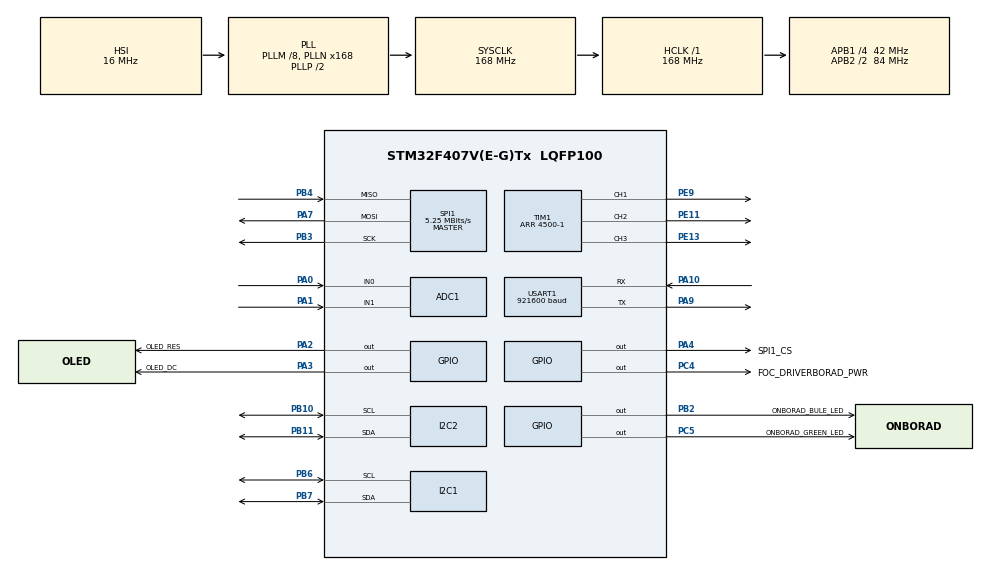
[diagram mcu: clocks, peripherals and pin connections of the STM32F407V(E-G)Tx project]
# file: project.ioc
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ADC1.Channel-4\#ChannelRegularConversion=ADC_CHANNEL_0
ADC1.Channel-8\#ChannelInjectedConversion=ADC_CHANNEL_0
ADC1.Channel-9\#ChannelInjectedConversion=ADC_CHANNEL_1
ADC1.ExternalTrigInjecConv=ADC_EXTERNALTRIGINJECCONV_T1_TRGO
ADC1.InjNumberOfConversion=2
ADC1.InjectedConvMode=None
ADC1.InjectedOffset-8\#ChannelInjectedConversion=0
ADC1.InjectedOffset-9\#ChannelInjectedConversion=0
ADC1.InjectedRank-8\#ChannelInjectedConversion=1
ADC1.InjectedRank-9\#ChannelInjectedConversion=2
ADC1.NbrOfConversion=1
ADC1.NbrOfConversionFlag=1
ADC1.Rank-4\#ChannelRegularConversion=1
ADC1.SamplingTime-4\#ChannelRegularConversion=ADC_SAMPLETIME_3CYCLES
ADC1.SamplingTime-8\#ChannelInjectedConversion=ADC_SAMPLETIME_15CYCLES
ADC1.SamplingTime-9\#ChannelInjectedConversion=ADC_SAMPLETIME_15CYCLES
ADC1.ScanConvMode=ENABLE
ADC1.master=1
Dma.I2C1_RX.1.Direction=DMA_PERIPH_TO_MEMORY
Dma.I2C1_RX.1.FIFOMode=DMA_FIFOMODE_DISABLE
Dma.I2C1_RX.1.Instance=DMA1_Stream0
Dma.I2C1_RX.1.MemDataAlignment=DMA_MDATAALIGN_BYTE
Dma.I2C1_RX.1.MemInc=DMA_MINC_ENABLE
Dma.I2C1_RX.1.Mode=DMA_NORMAL
Dma.I2C1_RX.1.PeriphDataAlignment=DMA_PDATAALIGN_BYTE
Dma.I2C1_RX.1.PeriphInc=DMA_PINC_DISABLE
Dma.I2C1_RX.1.Priority=DMA_PRIORITY_LOW
Dma.I2C2_RX.2.Direction=DMA_PERIPH_TO_MEMORY
Dma.I2C2_RX.2.FIFOMode=DMA_FIFOMODE_DISABLE
Dma.I2C2_RX.2.Instance=DMA1_Stream2
Dma.I2C2_RX.2.MemDataAlignment=DMA_MDATAALIGN_BYTE
Dma.I2C2_RX.2.MemInc=DMA_MINC_ENABLE
Dma.I2C2_RX.2.Mode=DMA_NORMAL
Dma.I2C2_RX.2.PeriphDataAlignment=DMA_PDATAALIGN_BYTE
Dma.I2C2_RX.2.PeriphInc=DMA_PINC_DISABLE
Dma.I2C2_RX.2.Priority=DMA_PRIORITY_LOW
Dma.Request0=USART1_TX
Dma.Request1=I2C1_RX
Dma.Request2=I2C2_RX
Dma.USART1_TX.0.Direction=DMA_MEMORY_TO_PERIPH
Dma.USART1_TX.0.FIFOMode=DMA_FIFOMODE_DISABLE
Dma.USART1_TX.0.Instance=DMA2_Stream7
Dma.USART1_TX.0.MemDataAlignment=DMA_MDATAALIGN_BYTE
Dma.USART1_TX.0.MemInc=DMA_MINC_ENABLE
Dma.USART1_TX.0.Mode=DMA_NORMAL
Dma.USART1_TX.0.PeriphDataAlignment=DMA_PDATAALIGN_BYTE
Dma.USART1_TX.0.PeriphInc=DMA_PINC_DISABLE
Dma.USART1_TX.0.Priority=DMA_PRIORITY_LOW
I2C1.I2C_Mode=I2C_Standard
I2C2.I2C_Mode=I2C_Standard
Mcu.Family=STM32F4
Mcu.Name=STM32F407V(E-G)Tx
Mcu.Package=LQFP100
NVIC.DMA1_Stream0_IRQn=true\:0\:0\:false\:false\:true\:false\:true\:true
NVIC.DMA1_Stream2_IRQn=true\:0\:0\:false\:false\:true\:false\:true\:true
NVIC.DMA2_Stream7_IRQn=true\:0\:0\:false\:false\:true\:false\:true\:true
NVIC.PriorityGroup=NVIC_PRIORITYGROUP_4
NVIC.TIM1_UP_TIM10_IRQn=true\:0\:0\:false\:false\:true\:true\:true\:true
NVIC.USART1_IRQn=true\:0\:0\:false\:false\:true\:true\:true\:true
PA0-WKUP.Signal=ADCx_IN0
PA1.Signal=ADCx_IN1
PA10.Mode=Asynchronous
PA10.Signal=USART1_RX
PA13.Mode=Serial_Wire
PA13.Signal=SYS_JTMS-SWDIO
PA14.Mode=Serial_Wire
PA14.Signal=SYS_JTCK-SWCLK
PA2.GPIO_Label=OLED_RES
PA2.GPIO_PuPd=GPIO_PULLUP
PA2.GPIO_Speed=GPIO_SPEED_FREQ_VERY_HIGH
PA2.PinState=GPIO_PIN_SET
PA2.Signal=GPIO_Output
PA3.GPIO_Label=OLED_DC
PA3.GPIO_PuPd=GPIO_PULLUP
PA3.GPIO_Speed=GPIO_SPEED_FREQ_VERY_HIGH
PA3.PinState=GPIO_PIN_SET
PA3.Signal=GPIO_Output
PA4.GPIO_Label=SPI1_CS
PA4.GPIO_PuPd=GPIO_PULLUP
PA4.GPIO_Speed=GPIO_SPEED_FREQ_VERY_HIGH
PA4.PinState=GPIO_PIN_SET
PA4.Signal=GPIO_Output
PA7.Mode=Full_Duplex_Master
PA7.Signal=SPI1_MOSI
PA9.Mode=Asynchronous
PA9.Signal=USART1_TX
PB10.Mode=I2C
PB10.Signal=I2C2_SCL
PB11.Mode=I2C
PB11.Signal=I2C2_SDA
PB2.GPIO_Label=ONBORAD_BULE_LED
PB2.GPIO_PuPd=GPIO_PULLUP
PB2.PinState=GPIO_PIN_SET
PB2.Signal=GPIO_Output
PB3.Mode=Full_Duplex_Master
PB3.Signal=SPI1_SCK
PB4.Mode=Full_Duplex_Master
PB4.Signal=SPI1_MISO
PB6.Mode=I2C
PB6.Signal=I2C1_SCL
PB7.Mode=I2C
PB7.Signal=I2C1_SDA
PC4.GPIO_Label=FOC_DRIVERBORAD_PWR
PC4.GPIO_PuPd=GPIO_NOPULL
PC4.Signal=GPIO_Output
PC5.GPIO_Label=ONBORAD_GREEN_LED
PC5.GPIO_PuPd=GPIO_PULLUP
PC5.PinState=GPIO_PIN_SET
PC5.Signal=GPIO_Output
PE11.Signal=S_TIM1_CH2
PE13.Signal=S_TIM1_CH3
PE9.Signal=S_TIM1_CH1
PH0-OSC_IN.Mode=HSE-External-Oscillator
PH0-OSC_IN.Signal=RCC_OSC_IN
PH1-OSC_OUT.Mode=HSE-External-Oscillator
PH1-OSC_OUT.Signal=RCC_OSC_OUT
ProjectManager.HeapSize=0x200
ProjectManager.StackSize=0x400
ProjectManager.TargetToolchain=MDK-ARM V5.32
RCC.48MHZClocksFreq_Value=84000000
RCC.AHBFreq_Value=168000000
RCC.APB1CLKDivider=RCC_HCLK_DIV4
RCC.APB1Freq_Value=42000000
RCC.APB1TimFreq_Value=84000000
RCC.APB2CLKDivider=RCC_HCLK_DIV2
RCC.APB2Freq_Value=84000000
RCC.APB2TimFreq_Value=168000000
RCC.CortexFreq_Value=168000000
RCC.HCLKFreq_Value=168000000
RCC.HSE_VALUE=25000000
RCC.HSI_VALUE=16000000
RCC.LSE_VALUE=32768
RCC.PLLM=8
RCC.PLLN=168
RCC.SYSCLKFreq_VALUE=168000000
RCC.SYSCLKSource=RCC_SYSCLKSOURCE_PLLCLK
RCC.VCOOutputFreq_Value=336000000
SH.ADCx_IN0.0=ADC1_IN0,IN0
SH.ADCx_IN1.0=ADC1_IN1,IN1
SH.S_TIM1_CH1.0=TIM1_CH1,PWM Generation1 CH1
SH.S_TIM1_CH2.0=TIM1_CH2,PWM Generation2 CH2
SH.S_TIM1_CH3.0=TIM1_CH3,PWM Generation3 CH3
SPI1.BaudRatePrescaler=SPI_BAUDRATEPRESCALER_16
SPI1.CalculateBaudRate=5.25 MBits/s
SPI1.Direction=SPI_DIRECTION_2LINES
SPI1.Mode=SPI_MODE_MASTER
SPI1.VirtualType=VM_MASTER
TIM1.AutoReloadPreload=TIM_AUTORELOAD_PRELOAD_ENABLE
TIM1.Channel-PWM\ Generation1\ CH1=TIM_CHANNEL_1
TIM1.Channel-PWM\ Generation2\ CH2=TIM_CHANNEL_2
TIM1.Channel-PWM\ Generation3\ CH3=TIM_CHANNEL_3
TIM1.CounterMode=TIM_COUNTERMODE_CENTERALIGNED3
TIM1.Period=4500-1
TIM1.Pulse-PWM\ Generation1\ CH1=2100
TIM1.Pulse-PWM\ Generation2\ CH2=2100
TIM1.Pulse-PWM\ Generation3\ CH3=2100
TIM1.RepetitionCounter=1
TIM1.TIM_MasterOutputTrigger=TIM_TRGO_UPDATE
TIM1.TIM_MasterSlaveMode=TIM_MASTERSLAVEMODE_ENABLE
USART1.BaudRate=921600
USART1.VirtualMode=VM_ASYNC
VP_TIM1_VS_ClockSourceINT.Mode=Internal
board=custom

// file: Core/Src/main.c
/* USER CODE BEGIN Header */
/**
  ******************************************************************************
  * @file           : main.c
  * @brief          : Main program body
  ******************************************************************************
  * @attention
  *
  * Copyright (c) 2026 STMicroelectronics.
  * All rights reserved.
  *
  * This software is licensed under terms that can be found in the LICENSE file
  * in the root directory of this software component.
  * If no LICENSE file comes with this software, it is provided AS-IS.
  *
  ******************************************************************************
  */
/* USER CODE END Header */
#include "main.h"

ADC_HandleTypeDef hadc1;

I2C_HandleTypeDef hi2c1;
I2C_HandleTypeDef hi2c2;
DMA_HandleTypeDef hdma_i2c1_rx;
DMA_HandleTypeDef hdma_i2c2_rx;

SPI_HandleTypeDef hspi1;

TIM_HandleTypeDef htim1;

UART_HandleTypeDef huart1;
DMA_HandleTypeDef hdma_usart1_tx;

void SystemClock_Config(void);
static void MX_GPIO_Init(void);
static void MX_DMA_Init(void);
static void MX_USART1_UART_Init(void);
static void MX_SPI1_Init(void);
static void MX_I2C1_Init(void);
static void MX_TIM1_Init(void);
static void MX_I2C2_Init(void);
static void MX_ADC1_Init(void);

int main(void)
{

  /* MCU Configuration--------------------------------------------------------*/

  /* Reset of all peripherals, Initializes the Flash interface and the Systick. */
  HAL_Init();

  /* Configure the system clock */
  SystemClock_Config();

  /* Initialize all configured peripherals */
  MX_GPIO_Init();
  MX_DMA_Init();
  MX_USART1_UART_Init();
  MX_SPI1_Init();
  MX_I2C1_Init();
  MX_TIM1_Init();
  MX_I2C2_Init();
  MX_ADC1_Init();
  /* USER CODE BEGIN 2 */
  start_init_all();
  /* USER CODE END 2 */

  /* Infinite loop */
  /* USER CODE BEGIN WHILE */
  while (1)
  {
    start_loop();
    /* USER CODE END WHILE */

  }
}

void SystemClock_Config(void)
{
  RCC_OscInitTypeDef RCC_OscInitStruct = {0};
  RCC_ClkInitTypeDef RCC_ClkInitStruct = {0};

  /** Configure the main internal regulator output voltage
  */
  __HAL_RCC_PWR_CLK_ENABLE();
  __HAL_PWR_VOLTAGESCALING_CONFIG(PWR_REGULATOR_VOLTAGE_SCALE1);

  /** Initializes the RCC Oscillators according to the specified parameters
  * in the RCC_OscInitTypeDef structure.
  */
  RCC_OscInitStruct.OscillatorType = RCC_OSCILLATORTYPE_HSI;
  RCC_OscInitStruct.HSIState = RCC_HSI_ON;
  RCC_OscInitStruct.HSICalibrationValue = RCC_HSICALIBRATION_DEFAULT;
  RCC_OscInitStruct.PLL.PLLState = RCC_PLL_ON;
  RCC_OscInitStruct.PLL.PLLSource = RCC_PLLSOURCE_HSI;
  RCC_OscInitStruct.PLL.PLLM = 8;
  RCC_OscInitStruct.PLL.PLLN = 168;
  RCC_OscInitStruct.PLL.PLLP = RCC_PLLP_DIV2;
  RCC_OscInitStruct.PLL.PLLQ = 4;
  if (HAL_RCC_OscConfig(&RCC_OscInitStruct) != HAL_OK)
  {
    Error_Handler();
  }

  /** Initializes the CPU, AHB and APB buses clocks
  */
  RCC_ClkInitStruct.ClockType = RCC_CLOCKTYPE_HCLK|RCC_CLOCKTYPE_SYSCLK
                              |RCC_CLOCKTYPE_PCLK1|RCC_CLOCKTYPE_PCLK2;
  RCC_ClkInitStruct.SYSCLKSource = RCC_SYSCLKSOURCE_PLLCLK;
  RCC_ClkInitStruct.AHBCLKDivider = RCC_SYSCLK_DIV1;
  RCC_ClkInitStruct.APB1CLKDivider = RCC_HCLK_DIV4;
  RCC_ClkInitStruct.APB2CLKDivider = RCC_HCLK_DIV2;

  if (HAL_RCC_ClockConfig(&RCC_ClkInitStruct, FLASH_LATENCY_5) != HAL_OK)
  {
    Error_Handler();
  }
}

static void MX_ADC1_Init(void)
{

  ADC_ChannelConfTypeDef sConfig = {0};
  ADC_InjectionConfTypeDef sConfigInjected = {0};

  /** Configure the global features of the ADC (Clock, Resolution, Data Alignment and number of conversion)
  */
  hadc1.Instance = ADC1;
  hadc1.Init.ClockPrescaler = ADC_CLOCK_SYNC_PCLK_DIV4;
  hadc1.Init.Resolution = ADC_RESOLUTION_12B;
  hadc1.Init.ScanConvMode = ENABLE;
  hadc1.Init.ContinuousConvMode = DISABLE;
  hadc1.Init.DiscontinuousConvMode = DISABLE;
  hadc1.Init.ExternalTrigConvEdge = ADC_EXTERNALTRIGCONVEDGE_NONE;
  hadc1.Init.ExternalTrigConv = ADC_SOFTWARE_START;
  hadc1.Init.DataAlign = ADC_DATAALIGN_RIGHT;
  hadc1.Init.NbrOfConversion = 1;
  hadc1.Init.DMAContinuousRequests = DISABLE;
  hadc1.Init.EOCSelection = ADC_EOC_SINGLE_CONV;
  if (HAL_ADC_Init(&hadc1) != HAL_OK)
  {
    Error_Handler();
  }

  /** Configure for the selected ADC regular channel its corresponding rank in the sequencer and its sample time.
  */
  sConfig.Channel = ADC_CHANNEL_0;
  sConfig.Rank = 1;
  sConfig.SamplingTime = ADC_SAMPLETIME_3CYCLES;
  if (HAL_ADC_ConfigChannel(&hadc1, &sConfig) != HAL_OK)
  {
    Error_Handler();
  }

  /** Configures for the selected ADC injected channel its corresponding rank in the sequencer and its sample time
  */
  sConfigInjected.InjectedChannel = ADC_CHANNEL_0;
  sConfigInjected.InjectedRank = 1;
  sConfigInjected.InjectedNbrOfConversion = 2;
  sConfigInjected.InjectedSamplingTime = ADC_SAMPLETIME_15CYCLES;
  sConfigInjected.ExternalTrigInjecConvEdge = ADC_EXTERNALTRIGINJECCONVEDGE_RISING;
  sConfigInjected.ExternalTrigInjecConv = ADC_EXTERNALTRIGINJECCONV_T1_TRGO;
  sConfigInjected.AutoInjectedConv = DISABLE;
  sConfigInjected.InjectedDiscontinuousConvMode = DISABLE;
  sConfigInjected.InjectedOffset = 0;
  if (HAL_ADCEx_InjectedConfigChannel(&hadc1, &sConfigInjected) != HAL_OK)
  {
    Error_Handler();
  }

  /** Configures for the selected ADC injected channel its corresponding rank in the sequencer and its sample time
  */
  sConfigInjected.InjectedChannel = ADC_CHANNEL_1;
  sConfigInjected.InjectedRank = 2;
  if (HAL_ADCEx_InjectedConfigChannel(&hadc1, &sConfigInjected) != HAL_OK)
  {
    Error_Handler();
  }

}

static void MX_I2C1_Init(void)
{

  hi2c1.Instance = I2C1;
  hi2c1.Init.ClockSpeed = 100000;
  hi2c1.Init.DutyCycle = I2C_DUTYCYCLE_2;
  hi2c1.Init.OwnAddress1 = 0;
  hi2c1.Init.AddressingMode = I2C_ADDRESSINGMODE_7BIT;
  hi2c1.Init.DualAddressMode = I2C_DUALADDRESS_DISABLE;
  hi2c1.Init.OwnAddress2 = 0;
  hi2c1.Init.GeneralCallMode = I2C_GENERALCALL_DISABLE;
  hi2c1.Init.NoStretchMode = I2C_NOSTRETCH_DISABLE;
  if (HAL_I2C_Init(&hi2c1) != HAL_OK)
  {
    Error_Handler();
  }

}

static void MX_I2C2_Init(void)
{

  hi2c2.Instance = I2C2;
  hi2c2.Init.ClockSpeed = 100000;
  hi2c2.Init.DutyCycle = I2C_DUTYCYCLE_2;
  hi2c2.Init.OwnAddress1 = 0;
  hi2c2.Init.AddressingMode = I2C_ADDRESSINGMODE_7BIT;
  hi2c2.Init.DualAddressMode = I2C_DUALADDRESS_DISABLE;
  hi2c2.Init.OwnAddress2 = 0;
  hi2c2.Init.GeneralCallMode = I2C_GENERALCALL_DISABLE;
  hi2c2.Init.NoStretchMode = I2C_NOSTRETCH_DISABLE;
  if (HAL_I2C_Init(&hi2c2) != HAL_OK)
  {
    Error_Handler();
  }

}

static void MX_SPI1_Init(void)
{

  /* SPI1 parameter configuration*/
  hspi1.Instance = SPI1;
  hspi1.Init.Mode = SPI_MODE_MASTER;
  hspi1.Init.Direction = SPI_DIRECTION_2LINES;
  hspi1.Init.DataSize = SPI_DATASIZE_8BIT;
  hspi1.Init.CLKPolarity = SPI_POLARITY_LOW;
  hspi1.Init.CLKPhase = SPI_PHASE_1EDGE;
  hspi1.Init.NSS = SPI_NSS_SOFT;
  hspi1.Init.BaudRatePrescaler = SPI_BAUDRATEPRESCALER_16;
  hspi1.Init.FirstBit = SPI_FIRSTBIT_MSB;
  hspi1.Init.TIMode = SPI_TIMODE_DISABLE;
  hspi1.Init.CRCCalculation = SPI_CRCCALCULATION_DISABLE;
  hspi1.Init.CRCPolynomial = 10;
  if (HAL_SPI_Init(&hspi1) != HAL_OK)
  {
    Error_Handler();
  }

}

static void MX_TIM1_Init(void)
{

  TIM_ClockConfigTypeDef sClockSourceConfig = {0};
  TIM_MasterConfigTypeDef sMasterConfig = {0};
  TIM_OC_InitTypeDef sConfigOC = {0};
  TIM_BreakDeadTimeConfigTypeDef sBreakDeadTimeConfig = {0};

  htim1.Instance = TIM1;
  htim1.Init.Prescaler = 0;
  htim1.Init.CounterMode = TIM_COUNTERMODE_CENTERALIGNED3;
  htim1.Init.Period = 4500-1;
  htim1.Init.ClockDivision = TIM_CLOCKDIVISION_DIV1;
  htim1.Init.RepetitionCounter = 1;
  htim1.Init.AutoReloadPreload = TIM_AUTORELOAD_PRELOAD_ENABLE;
  if (HAL_TIM_Base_Init(&htim1) != HAL_OK)
  {
    Error_Handler();
  }
  sClockSourceConfig.ClockSource = TIM_CLOCKSOURCE_INTERNAL;
  if (HAL_TIM_ConfigClockSource(&htim1, &sClockSourceConfig) != HAL_OK)
  {
    Error_Handler();
  }
  if (HAL_TIM_PWM_Init(&htim1) != HAL_OK)
  {
    Error_Handler();
  }
  sMasterConfig.MasterOutputTrigger = TIM_TRGO_UPDATE;
  sMasterConfig.MasterSlaveMode = TIM_MASTERSLAVEMODE_ENABLE;
  if (HAL_TIMEx_MasterConfigSynchronization(&htim1, &sMasterConfig) != HAL_OK)
  {
    Error_Handler();
  }
  sConfigOC.OCMode = TIM_OCMODE_PWM1;
  sConfigOC.Pulse = 2100;
  sConfigOC.OCPolarity = TIM_OCPOLARITY_HIGH;
  sConfigOC.OCNPolarity = TIM_OCNPOLARITY_HIGH;
  sConfigOC.OCFastMode = TIM_OCFAST_DISABLE;
  sConfigOC.OCIdleState = TIM_OCIDLESTATE_RESET;
  sConfigOC.OCNIdleState = TIM_OCNIDLESTATE_RESET;
  if (HAL_TIM_PWM_ConfigChannel(&htim1, &sConfigOC, TIM_CHANNEL_1) != HAL_OK)
  {
    Error_Handler();
  }
  if (HAL_TIM_PWM_ConfigChannel(&htim1, &sConfigOC, TIM_CHANNEL_2) != HAL_OK)
  {
    Error_Handler();
  }
  if (HAL_TIM_PWM_ConfigChannel(&htim1, &sConfigOC, TIM_CHANNEL_3) != HAL_OK)
  {
    Error_Handler();
  }
  sBreakDeadTimeConfig.OffStateRunMode = TIM_OSSR_DISABLE;
  sBreakDeadTimeConfig.OffStateIDLEMode = TIM_OSSI_DISABLE;
  sBreakDeadTimeConfig.LockLevel = TIM_LOCKLEVEL_OFF;
  sBreakDeadTimeConfig.DeadTime = 0;
  sBreakDeadTimeConfig.BreakState = TIM_BREAK_DISABLE;
  sBreakDeadTimeConfig.BreakPolarity = TIM_BREAKPOLARITY_HIGH;
  sBreakDeadTimeConfig.AutomaticOutput = TIM_AUTOMATICOUTPUT_DISABLE;
  if (HAL_TIMEx_ConfigBreakDeadTime(&htim1, &sBreakDeadTimeConfig) != HAL_OK)
  {
    Error_Handler();
  }
  HAL_TIM_MspPostInit(&htim1);

}

static void MX_USART1_UART_Init(void)
{

  huart1.Instance = USART1;
  huart1.Init.BaudRate = 921600;
  huart1.Init.WordLength = UART_WORDLENGTH_8B;
  huart1.Init.StopBits = UART_STOPBITS_1;
  huart1.Init.Parity = UART_PARITY_NONE;
  huart1.Init.Mode = UART_MODE_TX_RX;
  huart1.Init.HwFlowCtl = UART_HWCONTROL_NONE;
  huart1.Init.OverSampling = UART_OVERSAMPLING_16;
  if (HAL_UART_Init(&huart1) != HAL_OK)
  {
    Error_Handler();
  }

}

static void MX_DMA_Init(void)
{

  /* DMA controller clock enable */
  __HAL_RCC_DMA2_CLK_ENABLE();
  __HAL_RCC_DMA1_CLK_ENABLE();

  /* DMA interrupt init */
  /* DMA1_Stream0_IRQn interrupt configuration */
  HAL_NVIC_SetPriority(DMA1_Stream0_IRQn, 0, 0);
  HAL_NVIC_EnableIRQ(DMA1_Stream0_IRQn);
  /* DMA1_Stream2_IRQn interrupt configuration */
  HAL_NVIC_SetPriority(DMA1_Stream2_IRQn, 0, 0);
  HAL_NVIC_EnableIRQ(DMA1_Stream2_IRQn);
  /* DMA2_Stream7_IRQn interrupt configuration */
  HAL_NVIC_SetPriority(DMA2_Stream7_IRQn, 0, 0);
  HAL_NVIC_EnableIRQ(DMA2_Stream7_IRQn);

}

static void MX_GPIO_Init(void)
{
  GPIO_InitTypeDef GPIO_InitStruct = {0};

  /* GPIO Ports Clock Enable */
  __HAL_RCC_GPIOH_CLK_ENABLE();
  __HAL_RCC_GPIOA_CLK_ENABLE();
  __HAL_RCC_GPIOC_CLK_ENABLE();
  __HAL_RCC_GPIOB_CLK_ENABLE();
  __HAL_RCC_GPIOE_CLK_ENABLE();

  /*Configure GPIO pin Output Level */
  HAL_GPIO_WritePin(GPIOA, OLED_RES_Pin|OLED_DC_Pin|SPI1_CS_Pin, GPIO_PIN_SET);

  /*Configure GPIO pin Output Level */
  HAL_GPIO_WritePin(FOC_DRIVERBORAD_PWR_GPIO_Port, FOC_DRIVERBORAD_PWR_Pin, GPIO_PIN_RESET);

  /*Configure GPIO pin Output Level */
  HAL_GPIO_WritePin(ONBORAD_GREEN_LED_GPIO_Port, ONBORAD_GREEN_LED_Pin, GPIO_PIN_SET);

  /*Configure GPIO pin Output Level */
  HAL_GPIO_WritePin(ONBORAD_BULE_LED_GPIO_Port, ONBORAD_BULE_LED_Pin, GPIO_PIN_SET);

  /*Configure GPIO pins : OLED_RES_Pin OLED_DC_Pin SPI1_CS_Pin */
  GPIO_InitStruct.Pin = OLED_RES_Pin|OLED_DC_Pin|SPI1_CS_Pin;
  GPIO_InitStruct.Mode = GPIO_MODE_OUTPUT_PP;
  GPIO_InitStruct.Pull = GPIO_PULLUP;
  GPIO_InitStruct.Speed = GPIO_SPEED_FREQ_VERY_HIGH;
  HAL_GPIO_Init(GPIOA, &GPIO_InitStruct);

  /*Configure GPIO pin : FOC_DRIVERBORAD_PWR_Pin */
  GPIO_InitStruct.Pin = FOC_DRIVERBORAD_PWR_Pin;
  GPIO_InitStruct.Mode = GPIO_MODE_OUTPUT_PP;
  GPIO_InitStruct.Pull = GPIO_NOPULL;
  GPIO_InitStruct.Speed = GPIO_SPEED_FREQ_LOW;
  HAL_GPIO_Init(FOC_DRIVERBORAD_PWR_GPIO_Port, &GPIO_InitStruct);

  /*Configure GPIO pin : ONBORAD_GREEN_LED_Pin */
  GPIO_InitStruct.Pin = ONBORAD_GREEN_LED_Pin;
  GPIO_InitStruct.Mode = GPIO_MODE_OUTPUT_PP;
  GPIO_InitStruct.Pull = GPIO_PULLUP;
  GPIO_InitStruct.Speed = GPIO_SPEED_FREQ_LOW;
  HAL_GPIO_Init(ONBORAD_GREEN_LED_GPIO_Port, &GPIO_InitStruct);

  /*Configure GPIO pin : ONBORAD_BULE_LED_Pin */
  GPIO_InitStruct.Pin = ONBORAD_BULE_LED_Pin;
  GPIO_InitStruct.Mode = GPIO_MODE_OUTPUT_PP;
  GPIO_InitStruct.Pull = GPIO_PULLUP;
  GPIO_InitStruct.Speed = GPIO_SPEED_FREQ_LOW;
  HAL_GPIO_Init(ONBORAD_BULE_LED_GPIO_Port, &GPIO_InitStruct);

}

void Error_Handler(void)
{
  __disable_irq();
  while (1)
  {
  }
}
